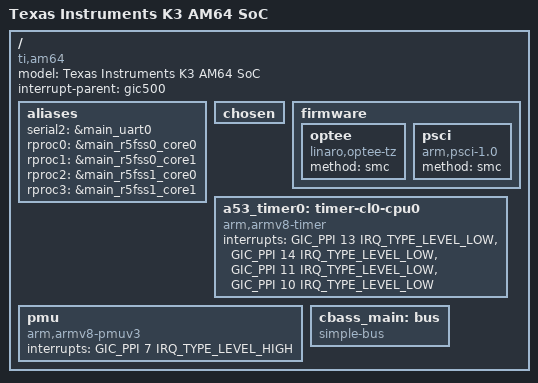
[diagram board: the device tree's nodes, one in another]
// SPDX-License-Identifier: GPL-2.0
/*
 * Device Tree Source for AM64 SoC Family
 *
 * Copyright (C) 2019-2020 Texas Instruments Incorporated - https://www.ti.com/
 */

#include <dt-bindings/gpio/gpio.h>
#include <dt-bindings/interrupt-controller/irq.h>
#include <dt-bindings/interrupt-controller/arm-gic.h>
#include <dt-bindings/pinctrl/k3.h>
#include <dt-bindings/soc/ti,sci_pm_domain.h>

/ {
	model = "Texas Instruments K3 AM64 SoC";
	compatible = "ti,am64";
	interrupt-parent = <&gic500>;
	#address-cells = <2>;
	#size-cells = <2>;

	aliases {
		serial2 = &main_uart0;
		rproc0 = &main_r5fss0_core0;
		rproc1 = &main_r5fss0_core1;
		rproc2 = &main_r5fss1_core0;
		rproc3 = &main_r5fss1_core1;
	};

	chosen { };

	firmware {
		optee {
			compatible = "linaro,optee-tz";
			method = "smc";
		};

		psci: psci {
			compatible = "arm,psci-1.0";
			method = "smc";
		};
	};

	a53_timer0: timer-cl0-cpu0 {
		compatible = "arm,armv8-timer";
		interrupts = <GIC_PPI 13 IRQ_TYPE_LEVEL_LOW>, /* cntpsirq */
			     <GIC_PPI 14 IRQ_TYPE_LEVEL_LOW>, /* cntpnsirq */
			     <GIC_PPI 11 IRQ_TYPE_LEVEL_LOW>, /* cntvirq */
			     <GIC_PPI 10 IRQ_TYPE_LEVEL_LOW>; /* cnthpirq */
	};

	pmu: pmu {
		compatible = "arm,armv8-pmuv3";
		/* Recommendation from GIC500 TRM Table A.3 */
		interrupts = <GIC_PPI 7 IRQ_TYPE_LEVEL_HIGH>;
	};

	cbass_main: bus {
		compatible = "simple-bus";
		#address-cells = <2>;
		#size-cells = <2>;
		u-boot,dm-spl;
		ranges;
	};
};

/* Now include the peripherals for each bus segments */
#include "k3-am64-main.dtsi"
